# SMS0_TIFS_CBASS_0_CBASS_GLB register map
Vendor: Texas Instruments
Peripheral module from a debugger description file (folder am62P).
Registers are 32-bit, read-only, reset 0x0 unless marked. A register's access mark holds for its fields unless they carry their own. Offsets are as the file gives them; lines under a group give offsets from that group; [hi:lo] are bit positions; {n}, {i} and the like mark numbered series; 'fields as' and 'values as' point back to an identical list; <NAME> marks a mode.

## SMS0_TIFS_CBASS_0_CBASS_GLB
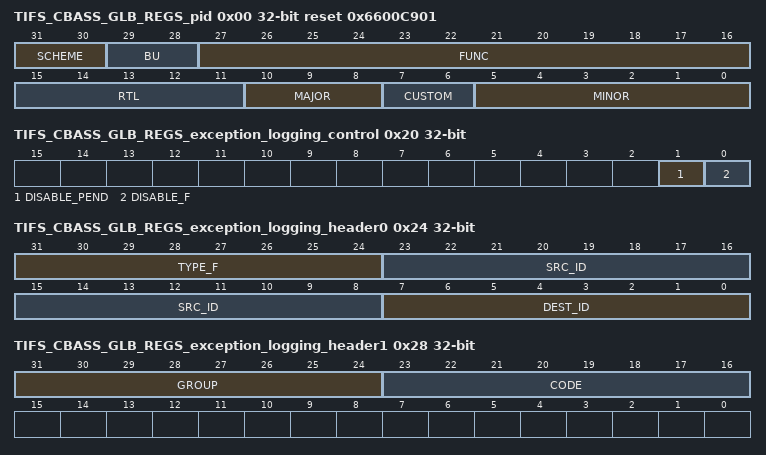
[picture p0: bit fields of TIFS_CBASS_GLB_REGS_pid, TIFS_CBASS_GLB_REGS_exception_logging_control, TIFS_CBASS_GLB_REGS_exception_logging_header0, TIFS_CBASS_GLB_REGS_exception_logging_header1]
0x00 TIFS_CBASS_GLB_REGS_pid reset 0x6600C901 — The Revision Register contains the major and minor revisions for the module.
  [31:30] SCHEME — PID register scheme
  [29:28] BU — Business Unit: 10 = Processors
  [27:16] FUNC — Module ID
  [15:11] RTL — RTL revision. Will vary depending on release.
  [10:8] MAJOR — Major revision
  [7:6] CUSTOM
  [5:0] MINOR — Minor revision
0x04 TIFS_CBASS_GLB_REGS_destination_id rw — The Destination ID Register defines the destination ID value for error messages.
  [7:0] DEST_ID — The destination ID.
0x20 TIFS_CBASS_GLB_REGS_exception_logging_control rw — The Exception Logging Control Register controls the exception logging.
  [1] DISABLE_PEND — Disables logging pending when set.
  [0] DISABLE_F — Disables logging when set.
0x24 TIFS_CBASS_GLB_REGS_exception_logging_header0 — The Exception Logging Header 0 Register contains the first word of the header.
  [31:24] TYPE_F — Type.
  [23:8] SRC_ID — Source ID.
  [7:0] DEST_ID — Destination ID.
0x28 TIFS_CBASS_GLB_REGS_exception_logging_header1 — The Exception Logging Header 1 Register contains the second word of the header.
  [31:24] GROUP, [23:16] CODE
0x2C TIFS_CBASS_GLB_REGS_exception_logging_data0 — The Exception Logging Data 0 Register contains the first word of the data.
  [31:0] ADDR_L — Address lower 32 bits.
0x30 TIFS_CBASS_GLB_REGS_exception_logging_data1 — The Exception Logging Data 1 Register contains the second word of the data.
  [15:0] ADDR_H — Address upper 16 bits.
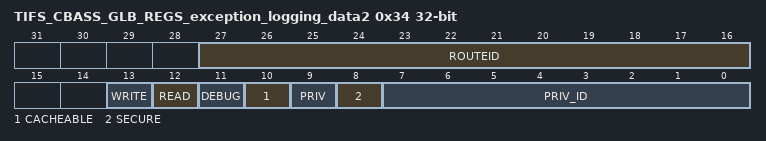
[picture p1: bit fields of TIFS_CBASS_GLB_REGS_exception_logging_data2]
0x34 TIFS_CBASS_GLB_REGS_exception_logging_data2 — The Exception Logging Data 2 Register contains the third word of the data.
  [27:16] ROUTEID, [13] WRITE, [12] READ, [11] DEBUG, [10] CACHEABLE, [9] PRIV, [8] SECURE, [7:0] PRIV_ID
0x38 TIFS_CBASS_GLB_REGS_exception_logging_data3 — The Exception Logging Data 3 Register contains the fourth word of the data.
  [9:0] BYTECNT — Byte count.
0x40 TIFS_CBASS_GLB_REGS_exception_pend_set access not given — The Exception Logging Pending Set Register allows to set the pend signal.
  [0] PEND_SET — Write a 1 to set the exception pend signal. (access R/W1TS)
0x44 TIFS_CBASS_GLB_REGS_exception_pend_clear access not given — The Exception Logging Pending Clear Register allows to clear the pend signal.
  [0] PEND_CLR — Write a 1 to clear the exception pend signal. (access R/W1TC)
